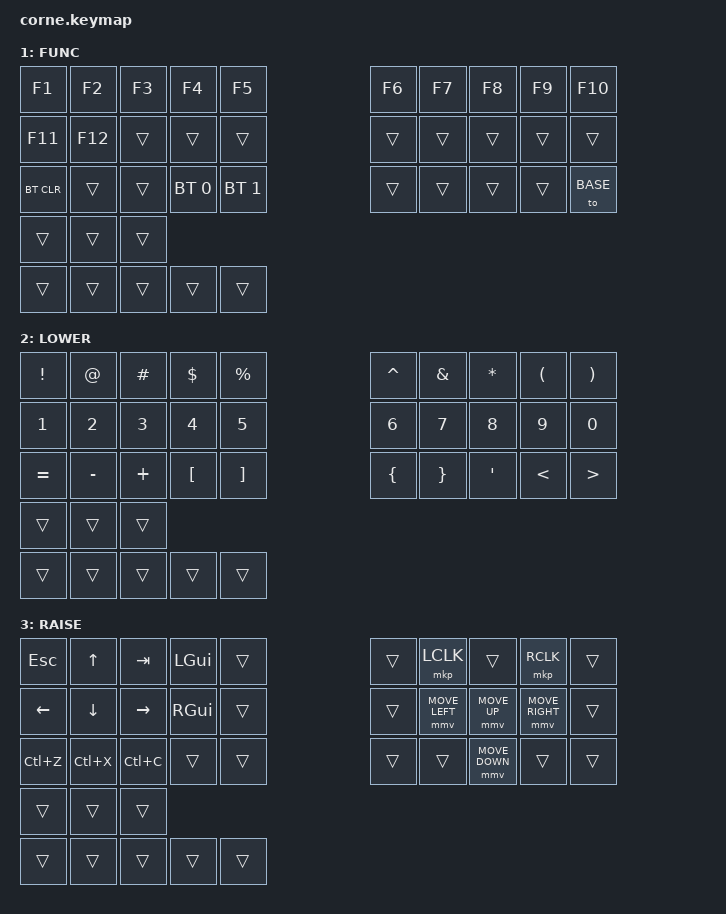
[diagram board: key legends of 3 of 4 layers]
/*
 * SPDX-License-Identifier: MIT
 */

#include <behaviors.dtsi>
#include <dt-bindings/zmk/keys.h>
#include <dt-bindings/zmk/bt.h>
#include <dt-bindings/zmk/pointing.h>

#define BASE  0
#define FUNC  1
#define LOWER 2
#define RAISE 3

/ {
    chosen {
        zmk,matrix_transform = &five_column_transform;
    };

    keymap {
        compatible = "zmk,keymap";

        /* ───────────────── BASE ───────────────── */
        base {
            bindings = <
                &kp Q &kp W &kp E &kp R &kp T        &kp Y &kp U &kp I &kp O &kp P
                &kp A &kp S &kp D &kp F &kp G        &kp H &kp J &kp K &kp L &kp SEMI
                &kp Z &kp X &kp C &kp V &kp B        &kp N &kp M &kp COMMA &kp DOT &kp SLASH

                &kp TAB   &kp LCTRL   &lt LOWER SPACE
                &lt RAISE ENTER &lt FUNC BSPC   &kp RSHFT
            >;
        };

        /* ─────────────── FUNC ─────────────── */
        func {
            label = "FUNC";
            bindings = <
                &kp F1      &kp F2  &kp F3  &kp F4        &kp F5             &kp F6 &kp F7 &kp F8 &kp F9 &kp F10
                &kp F11     &kp F12 &trans  &trans        &trans             &trans &trans &trans &trans &trans
                &bt BT_CLR  &trans  &trans  &bt BT_SEL 0  &bt BT_SEL 1       &trans &trans &trans &trans &to BASE

                &trans &trans &trans
                &trans &trans &trans &trans &trans
            >;
        };

        /* ─────────────── LOWER ─────────────── */
        lower {
            label = "LOWER";
            bindings = <
                &kp EXCL &kp AT &kp HASH &kp DLLR &kp PRCNT      &kp CARET &kp AMPS &kp ASTRK &kp LPAR &kp RPAR
                &kp N1   &kp N2 &kp N3   &kp N4   &kp N5         &kp N6    &kp N7   &kp N8    &kp N9   &kp N0
                &kp EQUAL &kp MINUS &kp PLUS &kp LBKT &kp RBKT  &kp LBRC &kp RBRC &kp APOS &kp LESS_THAN &kp GREATER_THAN

                &trans &trans &trans
                &trans &trans &trans &trans &trans
            >;
        };

        /* ─────────────── RAISE ─────────────── */
        raise {
            label = "RAISE";

            /* ┌───────────────┐        ┌─────────────────────────┐
             * │ ESC  ↑  TAB   │        │ LCLK      RCLK          │
             * │ ←   ↓   →     │        │ MOVE ←  MOVE ↑  MOVE → │
             * │ UNDO CUT COPY │        │        MOVE ↓          │
             * └───────────────┘        └─────────────────────────┘
             */

            bindings = <
                &kp ESC   &kp UP    &kp TAB   &kp LGUI &trans      &trans &mkp LCLK &trans        &mkp RCLK &trans
                &kp LEFT  &kp DOWN  &kp RIGHT &kp RGUI &trans      &trans &mmv MOVE_LEFT &mmv MOVE_UP &mmv MOVE_RIGHT &trans
                &kp LC(Z) &kp LC(X) &kp LC(C) &trans   &trans      &trans &trans &mmv MOVE_DOWN &trans &trans

                &trans &trans &trans
                &trans &trans &trans &trans &trans
            >;
        };
    };
};
